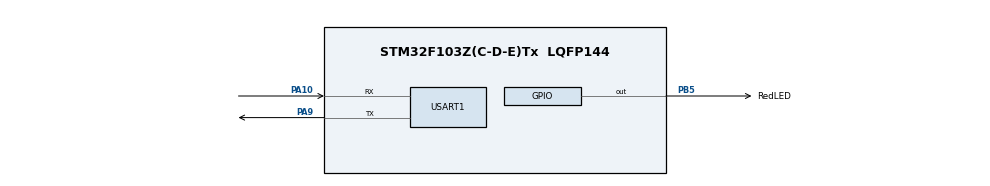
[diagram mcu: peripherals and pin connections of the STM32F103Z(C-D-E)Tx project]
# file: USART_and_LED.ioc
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Mcu.Family=STM32F1
Mcu.Name=STM32F103Z(C-D-E)Tx
Mcu.Package=LQFP144
NVIC.PriorityGroup=NVIC_PRIORITYGROUP_4
OSC_IN.Mode=HSE-External-Oscillator
OSC_IN.Signal=RCC_OSC_IN
OSC_OUT.Mode=HSE-External-Oscillator
OSC_OUT.Signal=RCC_OSC_OUT
PA10.Mode=Asynchronous
PA10.Signal=USART1_RX
PA13.Mode=Serial_Wire
PA13.Signal=SYS_JTMS-SWDIO
PA14.Mode=Serial_Wire
PA14.Signal=SYS_JTCK-SWCLK
PA9.Mode=Asynchronous
PA9.Signal=USART1_TX
PB5.GPIO_Label=RedLED
PB5.PinState=GPIO_PIN_SET
PB5.Signal=GPIO_Output
ProjectManager.HeapSize=0x200
ProjectManager.StackSize=0x400
ProjectManager.TargetToolchain=CMake
RCC.APB1Freq_Value=8000000
RCC.APB2Freq_Value=8000000
USART1.VirtualMode=VM_ASYNC
board=custom

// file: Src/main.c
/* USER CODE BEGIN Header */
/**
 ******************************************************************************
 * @file           : main.c
 * @brief          : Main program body
 ******************************************************************************
 * @attention
 *
 * Copyright (c) 2025 STMicroelectronics.
 * All rights reserved.
 *
 * This software is licensed under terms that can be found in the LICENSE file
 * in the root directory of this software component.
 * If no LICENSE file comes with this software, it is provided AS-IS.
 *
 ******************************************************************************
 */
/* USER CODE END Header */
#include "main.h"

#include <stdint.h>

#include "stm32f1xx_hal.h"
#include "stm32f1xx_hal_def.h"
#include "stm32f1xx_hal_uart.h"

UART_HandleTypeDef huart1;

void SystemClock_Config(void);
static void MX_GPIO_Init(void);
static void MX_USART1_UART_Init(void);

int main(void) {
    /* USER CODE BEGIN 1 */
    uint8_t msg = 0;
    /* USER CODE END 1 */

    /* MCU Configuration--------------------------------------------------------*/

    /* Reset of all peripherals, Initializes the Flash interface and the Systick.
     */
    HAL_Init();

    /* Configure the system clock */
    SystemClock_Config();

    /* Initialize all configured peripherals */
    MX_GPIO_Init();
    MX_USART1_UART_Init();

    /* Infinite loop */
    /* USER CODE BEGIN WHILE */
    while (1) {
        HAL_UART_Receive(&huart1, &msg, sizeof(msg), HAL_MAX_DELAY);

        switch (msg) {
            case '1': // Red LED ON
                HAL_GPIO_WritePin(RedLED_GPIO_Port, RedLED_Pin, GPIO_PIN_RESET);
                break;
            case '0': // Red LED OFF
                HAL_GPIO_WritePin(RedLED_GPIO_Port, RedLED_Pin, GPIO_PIN_SET);
                break;
            default: break;
        }

        HAL_UART_Transmit(&huart1, &msg, sizeof(msg), HAL_MAX_DELAY);

        // HAL_Delay(1000);

        /* USER CODE END WHILE */

    }
}

void SystemClock_Config(void) {
    RCC_OscInitTypeDef RCC_OscInitStruct = {0};
    RCC_ClkInitTypeDef RCC_ClkInitStruct = {0};

    /** Initializes the RCC Oscillators according to the specified parameters
     * in the RCC_OscInitTypeDef structure.
     */
    RCC_OscInitStruct.OscillatorType = RCC_OSCILLATORTYPE_HSI;
    RCC_OscInitStruct.HSIState = RCC_HSI_ON;
    RCC_OscInitStruct.HSICalibrationValue = RCC_HSICALIBRATION_DEFAULT;
    RCC_OscInitStruct.PLL.PLLState = RCC_PLL_NONE;
    if (HAL_RCC_OscConfig(&RCC_OscInitStruct) != HAL_OK) {
        Error_Handler();
    }

    /** Initializes the CPU, AHB and APB buses clocks
     */
    RCC_ClkInitStruct.ClockType = RCC_CLOCKTYPE_HCLK | RCC_CLOCKTYPE_SYSCLK | RCC_CLOCKTYPE_PCLK1 | RCC_CLOCKTYPE_PCLK2;
    RCC_ClkInitStruct.SYSCLKSource = RCC_SYSCLKSOURCE_HSI;
    RCC_ClkInitStruct.AHBCLKDivider = RCC_SYSCLK_DIV1;
    RCC_ClkInitStruct.APB1CLKDivider = RCC_HCLK_DIV1;
    RCC_ClkInitStruct.APB2CLKDivider = RCC_HCLK_DIV1;

    if (HAL_RCC_ClockConfig(&RCC_ClkInitStruct, FLASH_LATENCY_0) != HAL_OK) {
        Error_Handler();
    }
}

static void MX_USART1_UART_Init(void) {

    huart1.Instance = USART1;
    huart1.Init.BaudRate = 115200;
    huart1.Init.WordLength = UART_WORDLENGTH_8B;
    huart1.Init.StopBits = UART_STOPBITS_1;
    huart1.Init.Parity = UART_PARITY_NONE;
    huart1.Init.Mode = UART_MODE_TX_RX;
    huart1.Init.HwFlowCtl = UART_HWCONTROL_NONE;
    huart1.Init.OverSampling = UART_OVERSAMPLING_16;
    if (HAL_UART_Init(&huart1) != HAL_OK) {
        Error_Handler();
    }
}

static void MX_GPIO_Init(void) {
    GPIO_InitTypeDef GPIO_InitStruct = {0};

    /* GPIO Ports Clock Enable */
    __HAL_RCC_GPIOA_CLK_ENABLE();
    __HAL_RCC_GPIOB_CLK_ENABLE();

    /*Configure GPIO pin Output Level */
    HAL_GPIO_WritePin(RedLED_GPIO_Port, RedLED_Pin, GPIO_PIN_SET);

    /*Configure GPIO pin : RedLED_Pin */
    GPIO_InitStruct.Pin = RedLED_Pin;
    GPIO_InitStruct.Mode = GPIO_MODE_OUTPUT_PP;
    GPIO_InitStruct.Pull = GPIO_NOPULL;
    GPIO_InitStruct.Speed = GPIO_SPEED_FREQ_LOW;
    HAL_GPIO_Init(RedLED_GPIO_Port, &GPIO_InitStruct);

}

void Error_Handler(void) {
    __disable_irq();
    while (1) {}
}

#ifdef USE_FULL_ASSERT
/**
 * @brief  Reports the name of the source file and the source line number
 *         where the assert_param error has occurred.
 * @param  file: pointer to the source file name
 * @param  line: assert_param error line source number
 * @retval None
 */
void assert_failed(uint8_t* file, uint32_t line) {
    /* USER CODE BEGIN 6 */
    /* User can add his own implementation to report the file name and line
       number, ex: printf("Wrong parameters value: file %s on line %d\r\n", file,
       line) */
    /* USER CODE END 6 */
}
#endif /* USE_FULL_ASSERT */
